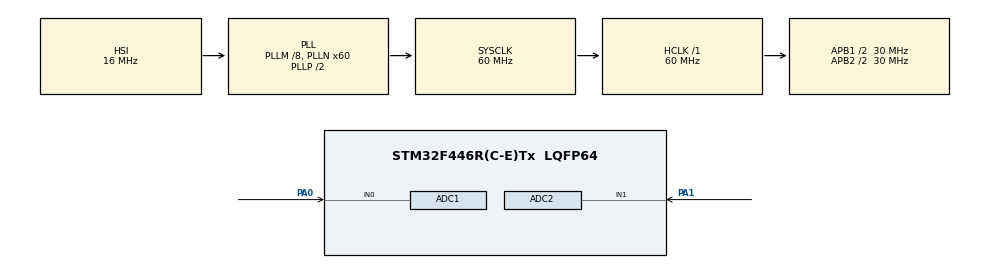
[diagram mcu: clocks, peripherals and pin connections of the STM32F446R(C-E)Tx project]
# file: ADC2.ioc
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ADC1.Channel-0\#ChannelRegularConversion=ADC_CHANNEL_0
ADC1.Channel-1\#ChannelRegularConversion=ADC_CHANNEL_VREFINT
ADC1.Channel-2\#ChannelRegularConversion=ADC_CHANNEL_TEMPSENSOR
ADC1.ContinuousConvMode=ENABLE
ADC1.NbrOfConversion=3
ADC1.NbrOfConversionFlag=1
ADC1.Rank-0\#ChannelRegularConversion=1
ADC1.Rank-1\#ChannelRegularConversion=2
ADC1.Rank-2\#ChannelRegularConversion=3
ADC1.SamplingTime-0\#ChannelRegularConversion=ADC_SAMPLETIME_480CYCLES
ADC1.SamplingTime-1\#ChannelRegularConversion=ADC_SAMPLETIME_480CYCLES
ADC1.SamplingTime-2\#ChannelRegularConversion=ADC_SAMPLETIME_480CYCLES
ADC1.ScanConvMode=ENABLE
ADC1.master=1
ADC2.Channel-0\#ChannelRegularConversion=ADC_CHANNEL_1
ADC2.ContinuousConvMode=ENABLE
ADC2.NbrOfConversionFlag=1
ADC2.Rank-0\#ChannelRegularConversion=1
ADC2.SamplingTime-0\#ChannelRegularConversion=ADC_SAMPLETIME_480CYCLES
Mcu.Family=STM32F4
Mcu.Name=STM32F446R(C-E)Tx
Mcu.Package=LQFP64
NVIC.ADC_IRQn=true\:0\:0\:false\:false\:true\:true\:true
NVIC.PriorityGroup=NVIC_PRIORITYGROUP_4
PA0-WKUP.Signal=ADCx_IN0
PA1.Signal=ADCx_IN1
PH0-OSC_IN.Mode=HSE-External-Oscillator
PH0-OSC_IN.Signal=RCC_OSC_IN
PH1-OSC_OUT.Mode=HSE-External-Oscillator
PH1-OSC_OUT.Signal=RCC_OSC_OUT
ProjectManager.HeapSize=0x200
ProjectManager.StackSize=0x400
ProjectManager.TargetToolchain=MDK-ARM V5.27
RCC.AHBFreq_Value=60000000
RCC.APB1CLKDivider=RCC_HCLK_DIV2
RCC.APB1Freq_Value=30000000
RCC.APB1TimFreq_Value=60000000
RCC.APB2CLKDivider=RCC_HCLK_DIV2
RCC.APB2Freq_Value=30000000
RCC.APB2TimFreq_Value=60000000
RCC.CortexFreq_Value=60000000
RCC.HCLKFreq_Value=60000000
RCC.HSE_VALUE=8000000
RCC.PLLM=8
RCC.PLLN=60
RCC.SYSCLKFreq_VALUE=60000000
RCC.SYSCLKSource=RCC_SYSCLKSOURCE_PLLCLK
RCC.USBFreq_Value=60000000
RCC.VCOOutputFreq_Value=120000000
SH.ADCx_IN0.0=ADC1_IN0,IN0
SH.ADCx_IN1.0=ADC2_IN1,IN1
VP_ADC1_TempSens_Input.Mode=IN-TempSens
VP_ADC1_Vref_Input.Mode=IN-Vrefint
board=custom

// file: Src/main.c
/* USER CODE BEGIN Header */
/**
  ******************************************************************************
  * @file           : main.c
  * @brief          : Main program body
  ******************************************************************************
  * @attention
  *
  * <h2><center>&copy; Copyright (c) 2020 STMicroelectronics.
  * All rights reserved.</center></h2>
  *
  * This software component is licensed by ST under BSD 3-Clause license,
  * the "License"; You may not use this file except in compliance with the
  * License. You may obtain a copy of the License at:
  *                        opensource.org/licenses/BSD-3-Clause
  *
  ******************************************************************************
  */
/* USER CODE END Header */

#include "main.h"
#define Vref_Cal ((uint16_t*)((uint32_t)0x1FFF7A2A))
#define avg_slope (float)0.025
#define V25 (float)0.76

/* USER CODE BEGIN Includes */
float Vadc1 = 0, Vadc2 = 0, VDDA = 0,temperature = 0,Vsense = 0;
int count = 0;
uint16_t adc_value[3],adc2_value = 0;
/* USER CODE END Includes */

ADC_HandleTypeDef hadc1;
ADC_HandleTypeDef hadc2;

void SystemClock_Config(void);
static void MX_GPIO_Init(void);
static void MX_ADC1_Init(void);
static void MX_ADC2_Init(void);

/* USER CODE BEGIN 0 */
void HAL_ADC_ConvCpltCallback(ADC_HandleTypeDef* hadc)
{
	if(__HAL_ADC_GET_FLAG(&hadc1, ADC_FLAG_EOC) != RESET)
		{
			adc_value[count] = HAL_ADC_GetValue(&hadc1);
			count++;
			if(count == 3)
				count = 0;

		}
		if(__HAL_ADC_GET_FLAG(&hadc2, ADC_FLAG_EOC) != RESET)
		{
			adc2_value = HAL_ADC_GetValue(&hadc2);
		}
		VDDA = (float)3.3*(*Vref_Cal)/adc_value[1];
		Vadc1 = VDDA*adc_value[0]/4095;
		Vadc2 = VDDA*adc2_value/4095;
		Vsense = VDDA*adc_value[2]/4095;

		temperature = ((Vsense - V25)/avg_slope)+25;
}
/* USER CODE END 0 */

int main(void)
{

  /* MCU Configuration--------------------------------------------------------*/

  /* Reset of all peripherals, Initializes the Flash interface and the Systick. */
  HAL_Init();

  /* Configure the system clock */
  SystemClock_Config();

  /* Initialize all configured peripherals */
  MX_GPIO_Init();
  MX_ADC1_Init();
  MX_ADC2_Init();
	HAL_ADC_Start_IT(&hadc1);
	HAL_ADC_Start_IT(&hadc2);
  /* Infinite loop */
  while (1)
  {

  }
}

void SystemClock_Config(void)
{
  RCC_OscInitTypeDef RCC_OscInitStruct = {0};
  RCC_ClkInitTypeDef RCC_ClkInitStruct = {0};

  /** Configure the main internal regulator output voltage
  */
  __HAL_RCC_PWR_CLK_ENABLE();
  __HAL_PWR_VOLTAGESCALING_CONFIG(PWR_REGULATOR_VOLTAGE_SCALE3);
  /** Initializes the CPU, AHB and APB busses clocks
  */
  RCC_OscInitStruct.OscillatorType = RCC_OSCILLATORTYPE_HSI;
  RCC_OscInitStruct.HSIState = RCC_HSI_ON;
  RCC_OscInitStruct.HSICalibrationValue = RCC_HSICALIBRATION_DEFAULT;
  RCC_OscInitStruct.PLL.PLLState = RCC_PLL_ON;
  RCC_OscInitStruct.PLL.PLLSource = RCC_PLLSOURCE_HSI;
  RCC_OscInitStruct.PLL.PLLM = 8;
  RCC_OscInitStruct.PLL.PLLN = 60;
  RCC_OscInitStruct.PLL.PLLP = RCC_PLLP_DIV2;
  RCC_OscInitStruct.PLL.PLLQ = 2;
  RCC_OscInitStruct.PLL.PLLR = 2;
  if (HAL_RCC_OscConfig(&RCC_OscInitStruct) != HAL_OK)
  {
    Error_Handler();
  }
  /** Initializes the CPU, AHB and APB busses clocks
  */
  RCC_ClkInitStruct.ClockType = RCC_CLOCKTYPE_HCLK|RCC_CLOCKTYPE_SYSCLK
                              |RCC_CLOCKTYPE_PCLK1|RCC_CLOCKTYPE_PCLK2;
  RCC_ClkInitStruct.SYSCLKSource = RCC_SYSCLKSOURCE_PLLCLK;
  RCC_ClkInitStruct.AHBCLKDivider = RCC_SYSCLK_DIV1;
  RCC_ClkInitStruct.APB1CLKDivider = RCC_HCLK_DIV2;
  RCC_ClkInitStruct.APB2CLKDivider = RCC_HCLK_DIV2;

  if (HAL_RCC_ClockConfig(&RCC_ClkInitStruct, FLASH_LATENCY_1) != HAL_OK)
  {
    Error_Handler();
  }
}

static void MX_ADC1_Init(void)
{

  ADC_ChannelConfTypeDef sConfig = {0};

  /** Configure the global features of the ADC (Clock, Resolution, Data Alignment and number of conversion)
  */
  hadc1.Instance = ADC1;
  hadc1.Init.ClockPrescaler = ADC_CLOCK_SYNC_PCLK_DIV2;
  hadc1.Init.Resolution = ADC_RESOLUTION_12B;
  hadc1.Init.ScanConvMode = ENABLE;
  hadc1.Init.ContinuousConvMode = ENABLE;
  hadc1.Init.DiscontinuousConvMode = DISABLE;
  hadc1.Init.ExternalTrigConvEdge = ADC_EXTERNALTRIGCONVEDGE_NONE;
  hadc1.Init.ExternalTrigConv = ADC_SOFTWARE_START;
  hadc1.Init.DataAlign = ADC_DATAALIGN_RIGHT;
  hadc1.Init.NbrOfConversion = 3;
  hadc1.Init.DMAContinuousRequests = DISABLE;
  hadc1.Init.EOCSelection = ADC_EOC_SINGLE_CONV;
  if (HAL_ADC_Init(&hadc1) != HAL_OK)
  {
    Error_Handler();
  }
  /** Configure for the selected ADC regular channel its corresponding rank in the sequencer and its sample time.
  */
  sConfig.Channel = ADC_CHANNEL_0;
  sConfig.Rank = 1;
  sConfig.SamplingTime = ADC_SAMPLETIME_480CYCLES;
  if (HAL_ADC_ConfigChannel(&hadc1, &sConfig) != HAL_OK)
  {
    Error_Handler();
  }
  /** Configure for the selected ADC regular channel its corresponding rank in the sequencer and its sample time.
  */
  sConfig.Channel = ADC_CHANNEL_VREFINT;
  sConfig.Rank = 2;
  if (HAL_ADC_ConfigChannel(&hadc1, &sConfig) != HAL_OK)
  {
    Error_Handler();
  }
  /** Configure for the selected ADC regular channel its corresponding rank in the sequencer and its sample time.
  */
  sConfig.Channel = ADC_CHANNEL_TEMPSENSOR;
  sConfig.Rank = 3;
  if (HAL_ADC_ConfigChannel(&hadc1, &sConfig) != HAL_OK)
  {
    Error_Handler();
  }

}

static void MX_ADC2_Init(void)
{

  ADC_ChannelConfTypeDef sConfig = {0};

  /** Configure the global features of the ADC (Clock, Resolution, Data Alignment and number of conversion)
  */
  hadc2.Instance = ADC2;
  hadc2.Init.ClockPrescaler = ADC_CLOCK_SYNC_PCLK_DIV2;
  hadc2.Init.Resolution = ADC_RESOLUTION_12B;
  hadc2.Init.ScanConvMode = DISABLE;
  hadc2.Init.ContinuousConvMode = ENABLE;
  hadc2.Init.DiscontinuousConvMode = DISABLE;
  hadc2.Init.ExternalTrigConvEdge = ADC_EXTERNALTRIGCONVEDGE_NONE;
  hadc2.Init.ExternalTrigConv = ADC_SOFTWARE_START;
  hadc2.Init.DataAlign = ADC_DATAALIGN_RIGHT;
  hadc2.Init.NbrOfConversion = 1;
  hadc2.Init.DMAContinuousRequests = DISABLE;
  hadc2.Init.EOCSelection = ADC_EOC_SINGLE_CONV;
  if (HAL_ADC_Init(&hadc2) != HAL_OK)
  {
    Error_Handler();
  }
  /** Configure for the selected ADC regular channel its corresponding rank in the sequencer and its sample time.
  */
  sConfig.Channel = ADC_CHANNEL_1;
  sConfig.Rank = 1;
  sConfig.SamplingTime = ADC_SAMPLETIME_480CYCLES;
  if (HAL_ADC_ConfigChannel(&hadc2, &sConfig) != HAL_OK)
  {
    Error_Handler();
  }

}

static void MX_GPIO_Init(void)
{

  /* GPIO Ports Clock Enable */
  __HAL_RCC_GPIOH_CLK_ENABLE();
  __HAL_RCC_GPIOA_CLK_ENABLE();

}

void Error_Handler(void)
{
}

/************************ (C) COPYRIGHT STMicroelectronics *****END OF FILE****/
